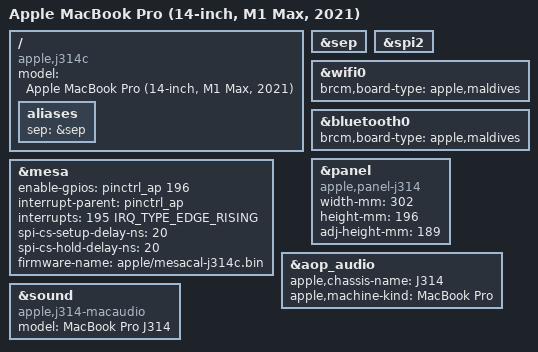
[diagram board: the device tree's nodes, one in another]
// SPDX-License-Identifier: GPL-2.0+ OR MIT
/*
 * MacBook Pro (14-inch, M1 Max, 2021)
 *
 * target-type: J314c
 *
 * Copyright The Asahi Linux Contributors
 */

/dts-v1/;

#include "t6001.dtsi"
#include "t600x-j314-j316.dtsi"

/ {
	compatible = "apple,j314c", "apple,t6001", "apple,arm-platform";
	model = "Apple MacBook Pro (14-inch, M1 Max, 2021)";

	aliases {
		sep = &sep;
	};
};

/*
 * m1n1 keys off the sep alias to add the sepfw region and the boot
 * manifests the driver needs to cold-boot SEPOS.
 */
&sep {
	status = "okay";
};

/*
 * The J314s/J316s lines, read from those machines' platform device trees
 * (/arm-io/spi2/mesa) and identical on the 14" and 16" M1 Pro: the power
 * line is gpio0 pin 196 (function-mesa_pwr, active high) and the data-ready
 * line is pin 195. The M1 Max boards share this family's board file,
 * t600x-j314-j316.dtsi. J314c's own platform device tree has not been
 * checked yet, and J314c is untested.
 */
&spi2 {
	status = "okay";
};

&mesa {
	status = "okay";
	enable-gpios = <&pinctrl_ap 196 GPIO_ACTIVE_HIGH>;
	interrupt-parent = <&pinctrl_ap>;
	interrupts = <195 IRQ_TYPE_EDGE_RISING>;
	spi-cs-setup-delay-ns = <20>;
	spi-cs-hold-delay-ns = <20>;
	/*
	 * Per-device factory data, extracted from this machine's own macOS
	 * install; it is not redistributable.
	 */
	firmware-name = "apple/mesacal-j314c.bin";
};

&wifi0 {
	brcm,board-type = "apple,maldives";
};

&bluetooth0 {
	brcm,board-type = "apple,maldives";
};

&panel {
	compatible = "apple,panel-j314", "apple,panel-mini-led", "apple,panel";
	width-mm = <302>;
	height-mm = <196>;
	adj-height-mm = <189>;
};

&aop_audio {
	apple,chassis-name = "J314";
	apple,machine-kind = "MacBook Pro";
};

&sound {
	compatible = "apple,j314-macaudio", "apple,macaudio";
	model = "MacBook Pro J314";
};
